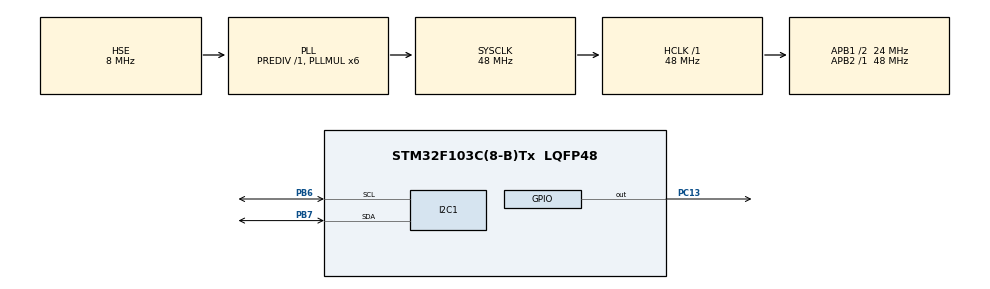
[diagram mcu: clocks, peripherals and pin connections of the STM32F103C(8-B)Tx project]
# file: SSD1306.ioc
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FREERTOS.Tasks01=defaultTask,0,128,StartDefaultTask,Default;SSD1306,0,128,SSD1306_Start,Default
Mcu.Family=STM32F1
Mcu.Name=STM32F103C(8-B)Tx
Mcu.Package=LQFP48
NVIC.PriorityGroup=NVIC_PRIORITYGROUP_4
PA13.Mode=Serial_Wire
PA13.Signal=SYS_JTMS-SWDIO
PA14.Mode=Serial_Wire
PA14.Signal=SYS_JTCK-SWCLK
PB6.Mode=I2C
PB6.Signal=I2C1_SCL
PB7.Mode=I2C
PB7.Signal=I2C1_SDA
PC13-TAMPER-RTC.Signal=GPIO_Output
PC14-OSC32_IN.Mode=LSE-External-Oscillator
PC14-OSC32_IN.Signal=RCC_OSC32_IN
PC15-OSC32_OUT.Mode=LSE-External-Oscillator
PC15-OSC32_OUT.Signal=RCC_OSC32_OUT
PD0-OSC_IN.Mode=HSE-External-Oscillator
PD0-OSC_IN.Signal=RCC_OSC_IN
PD1-OSC_OUT.Mode=HSE-External-Oscillator
PD1-OSC_OUT.Signal=RCC_OSC_OUT
ProjectManager.HeapSize=0x200
ProjectManager.StackSize=0x400
ProjectManager.TargetToolchain=MDK-ARM V5
RCC.AHBFreq_Value=48000000
RCC.APB1CLKDivider=RCC_HCLK_DIV2
RCC.APB1Freq_Value=24000000
RCC.APB1TimFreq_Value=48000000
RCC.APB2Freq_Value=48000000
RCC.APB2TimFreq_Value=48000000
RCC.HCLKFreq_Value=48000000
RCC.PLLMUL=RCC_PLL_MUL6
RCC.PLLSourceVirtual=RCC_PLLSOURCE_HSE
RCC.SYSCLKFreq_VALUE=48000000
RCC.SYSCLKSource=RCC_SYSCLKSOURCE_PLLCLK
RCC.USBFreq_Value=48000000
VP_FREERTOS_VS_ENABLE.Mode=Enabled
board=SSD1306

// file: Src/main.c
/**
  ******************************************************************************
  * File Name          : main.c
  * Description        : Main program body
  ******************************************************************************
  *
  * Copyright (c) 2017 STMicroelectronics International N.V.
  * All rights reserved.
  *
  * Redistribution and use in source and binary forms, with or without
  * modification, are permitted, provided that the following conditions are met:
  *
  * 1. Redistribution of source code must retain the above copyright notice,
  *    this list of conditions and the following disclaimer.
  * 2. Redistributions in binary form must reproduce the above copyright notice,
  *    this list of conditions and the following disclaimer in the documentation
  *    and/or other materials provided with the distribution.
  * 3. Neither the name of STMicroelectronics nor the names of other
  *    contributors to this software may be used to endorse or promote products
  *    derived from this software without specific written permission.
  * 4. This software, including modifications and/or derivative works of this
  *    software, must execute solely and exclusively on microcontroller or
  *    microprocessor devices manufactured by or for STMicroelectronics.
  * 5. Redistribution and use of this software other than as permitted under
  *    this license is void and will automatically terminate your rights under
  *    this license.
  *
  * THIS SOFTWARE IS PROVIDED BY STMICROELECTRONICS AND CONTRIBUTORS "AS IS"
  * AND ANY EXPRESS, IMPLIED OR STATUTORY WARRANTIES, INCLUDING, BUT NOT
  * LIMITED TO, THE IMPLIED WARRANTIES OF MERCHANTABILITY, FITNESS FOR A
  * PARTICULAR PURPOSE AND NON-INFRINGEMENT OF THIRD PARTY INTELLECTUAL PROPERTY
  * RIGHTS ARE DISCLAIMED TO THE FULLEST EXTENT PERMITTED BY LAW. IN NO EVENT
  * SHALL STMICROELECTRONICS OR CONTRIBUTORS BE LIABLE FOR ANY DIRECT, INDIRECT,
  * INCIDENTAL, SPECIAL, EXEMPLARY, OR CONSEQUENTIAL DAMAGES (INCLUDING, BUT NOT
  * LIMITED TO, PROCUREMENT OF SUBSTITUTE GOODS OR SERVICES; LOSS OF USE, DATA,
  * OR PROFITS; OR BUSINESS INTERRUPTION) HOWEVER CAUSED AND ON ANY THEORY OF
  * LIABILITY, WHETHER IN CONTRACT, STRICT LIABILITY, OR TORT (INCLUDING
  * NEGLIGENCE OR OTHERWISE) ARISING IN ANY WAY OUT OF THE USE OF THIS SOFTWARE,
  * EVEN IF ADVISED OF THE POSSIBILITY OF SUCH DAMAGE.
  *
  ******************************************************************************
  */
#include "main.h"
#include "stm32f1xx_hal.h"
#include "cmsis_os.h"

/* USER CODE BEGIN Includes */
#include "ssd1306.h"
/* USER CODE END Includes */

I2C_HandleTypeDef hi2c1;

osThreadId defaultTaskHandle;
osThreadId SSD1306Handle;

/* USER CODE BEGIN PV */
/* Private variables ---------------------------------------------------------*/

/* USER CODE END PV */

void SystemClock_Config(void);
void Error_Handler(void);
static void MX_GPIO_Init(void);
static void MX_I2C1_Init(void);
void StartDefaultTask(void const * argument);
void SSD1306_Start(void const * argument);

/* USER CODE BEGIN PFP */
/* Private function prototypes -----------------------------------------------*/

/* USER CODE END PFP */

int main(void)
{

  /* MCU Configuration----------------------------------------------------------*/

  /* Reset of all peripherals, Initializes the Flash interface and the Systick. */
  HAL_Init();

  /* Configure the system clock */
  SystemClock_Config();

  /* Initialize all configured peripherals */
  MX_GPIO_Init();
  MX_I2C1_Init();

  /* Create the thread(s) */
  /* definition and creation of defaultTask */
  osThreadDef(defaultTask, StartDefaultTask, osPriorityNormal, 0, 128);
  defaultTaskHandle = osThreadCreate(osThread(defaultTask), NULL);

  /* definition and creation of SSD1306 */
  osThreadDef(SSD1306, SSD1306_Start, osPriorityNormal, 0, 128);
  SSD1306Handle = osThreadCreate(osThread(SSD1306), NULL);

  /* Start scheduler */
  osKernelStart();

  /* We should never get here as control is now taken by the scheduler */

  /* Infinite loop */
  while (1)
  {

  }

}

/** System Clock Configuration
*/
void SystemClock_Config(void)
{

  RCC_OscInitTypeDef RCC_OscInitStruct;
  RCC_ClkInitTypeDef RCC_ClkInitStruct;

    /**Initializes the CPU, AHB and APB busses clocks
    */
  RCC_OscInitStruct.OscillatorType = RCC_OSCILLATORTYPE_HSE;
  RCC_OscInitStruct.HSEState = RCC_HSE_ON;
  RCC_OscInitStruct.HSEPredivValue = RCC_HSE_PREDIV_DIV1;
  RCC_OscInitStruct.HSIState = RCC_HSI_ON;
  RCC_OscInitStruct.PLL.PLLState = RCC_PLL_ON;
  RCC_OscInitStruct.PLL.PLLSource = RCC_PLLSOURCE_HSE;
  RCC_OscInitStruct.PLL.PLLMUL = RCC_PLL_MUL6;
  if (HAL_RCC_OscConfig(&RCC_OscInitStruct) != HAL_OK)
  {
    Error_Handler();
  }

    /**Initializes the CPU, AHB and APB busses clocks
    */
  RCC_ClkInitStruct.ClockType = RCC_CLOCKTYPE_HCLK|RCC_CLOCKTYPE_SYSCLK
                              |RCC_CLOCKTYPE_PCLK1|RCC_CLOCKTYPE_PCLK2;
  RCC_ClkInitStruct.SYSCLKSource = RCC_SYSCLKSOURCE_PLLCLK;
  RCC_ClkInitStruct.AHBCLKDivider = RCC_SYSCLK_DIV1;
  RCC_ClkInitStruct.APB1CLKDivider = RCC_HCLK_DIV2;
  RCC_ClkInitStruct.APB2CLKDivider = RCC_HCLK_DIV1;

  if (HAL_RCC_ClockConfig(&RCC_ClkInitStruct, FLASH_LATENCY_1) != HAL_OK)
  {
    Error_Handler();
  }

    /**Configure the Systick interrupt time
    */
  HAL_SYSTICK_Config(HAL_RCC_GetHCLKFreq()/1000);

    /**Configure the Systick
    */
  HAL_SYSTICK_CLKSourceConfig(SYSTICK_CLKSOURCE_HCLK);

  /* SysTick_IRQn interrupt configuration */
  HAL_NVIC_SetPriority(SysTick_IRQn, 15, 0);
}

/* I2C1 init function */
static void MX_I2C1_Init(void)
{

  hi2c1.Instance = I2C1;
  hi2c1.Init.ClockSpeed = 100000;
  hi2c1.Init.DutyCycle = I2C_DUTYCYCLE_2;
  hi2c1.Init.OwnAddress1 = 0;
  hi2c1.Init.AddressingMode = I2C_ADDRESSINGMODE_7BIT;
  hi2c1.Init.DualAddressMode = I2C_DUALADDRESS_DISABLE;
  hi2c1.Init.OwnAddress2 = 0;
  hi2c1.Init.GeneralCallMode = I2C_GENERALCALL_DISABLE;
  hi2c1.Init.NoStretchMode = I2C_NOSTRETCH_DISABLE;
  if (HAL_I2C_Init(&hi2c1) != HAL_OK)
  {
    Error_Handler();
  }

}

/** Configure pins as
        * Analog
        * Input
        * Output
        * EVENT_OUT
        * EXTI
*/
static void MX_GPIO_Init(void)
{

  GPIO_InitTypeDef GPIO_InitStruct;

  /* GPIO Ports Clock Enable */
  __HAL_RCC_GPIOC_CLK_ENABLE();
  __HAL_RCC_GPIOD_CLK_ENABLE();
  __HAL_RCC_GPIOA_CLK_ENABLE();
  __HAL_RCC_GPIOB_CLK_ENABLE();

  /*Configure GPIO pin Output Level */
  HAL_GPIO_WritePin(GPIOC, GPIO_PIN_13, GPIO_PIN_RESET);

  /*Configure GPIO pin : PC13 */
  GPIO_InitStruct.Pin = GPIO_PIN_13;
  GPIO_InitStruct.Mode = GPIO_MODE_OUTPUT_PP;
  GPIO_InitStruct.Speed = GPIO_SPEED_FREQ_LOW;
  HAL_GPIO_Init(GPIOC, &GPIO_InitStruct);

}

/* StartDefaultTask function */
void StartDefaultTask(void const * argument)
{

  for(;;)
  {
  }
}

/* SSD1306_Start function */
void SSD1306_Start(void const * argument)
{
  static uint32_t y;
  osDelay(1000);
  /* USER CODE BEGIN SSD1306_Start */
  ssd1306_Init();
  osDelay(1000);
  y = 0;
  ssd1306_SetCursor(0, y);
  ssd1306_WriteString("Hello, habrahabr!!", Font_7x10, White);//SSD1306_Fill(SSD1306_COLOR_WHITE);
  ssd1306_UpdateScreen();
  ssd1306_Fill(Black);
  /* Infinite loop */
  for(;;)
  {
    ssd1306_SetCursor(0, y++);
    if(y>63) y=0;
    ssd1306_DrawPixel(y,y,Black);
    ssd1306_WriteString("LONG STRING LONG STRING LONG STRING", Font_7x10, White);//SSD1306_Fill(SSD1306_COLOR_WHITE);
    ssd1306_UpdateScreen();
    ssd1306_Fill(Black);
    osDelay(500);
  }
  /* USER CODE END SSD1306_Start */
}

void Error_Handler(void)
{
  while(1)
  {
  }
}

/************************ (C) COPYRIGHT STMicroelectronics *****END OF FILE****/
